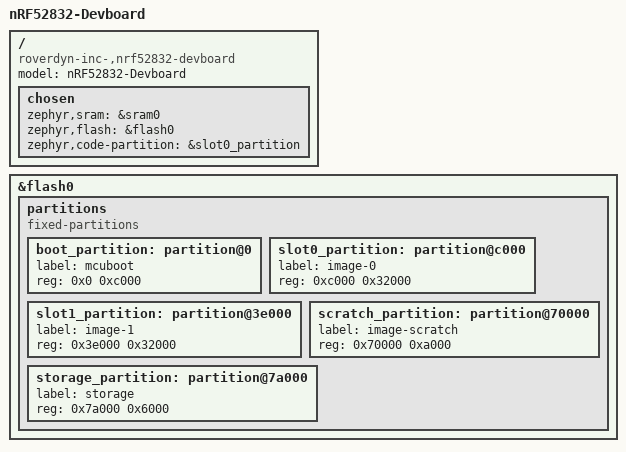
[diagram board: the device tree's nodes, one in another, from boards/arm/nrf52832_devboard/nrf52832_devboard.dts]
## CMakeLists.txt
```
cmake_minimum_required(VERSION 3.20.0)
find_package(Zephyr REQUIRED HINTS $ENV{ZEPHYR_BASE})

project(RTC-Interrupt-Examples)

target_sources(app PRIVATE src/main.c)
```

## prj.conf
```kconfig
# Config Debugger
CONFIG_CONSOLE=y
CONFIG_USE_SEGGER_RTT=y
CONFIG_RTT_CONSOLE=y
CONFIG_LOG=y
```

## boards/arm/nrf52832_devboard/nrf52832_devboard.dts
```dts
// Copyright (c) 2024 Nordic Semiconductor ASA
// SPDX-License-Identifier: Apache-2.0

/dts-v1/;
#include <nordic/nrf52832_qfaa.dtsi>

/ {
	model = "nRF52832-Devboard";
	compatible = "roverdyn-inc-,nrf52832-devboard";

	chosen {
		zephyr,sram = &sram0;
		zephyr,flash = &flash0;
		zephyr,code-partition = &slot0_partition;
	};
};

&flash0 {
	partitions {
		compatible = "fixed-partitions";
		#address-cells = <1>;
		#size-cells = <1>;

		boot_partition: partition@0 {
			label = "mcuboot";
			reg = <0x0 0xc000>;
		};
		slot0_partition: partition@c000 {
			label = "image-0";
			reg = <0xc000 0x32000>;
		};
		slot1_partition: partition@3e000 {
			label = "image-1";
			reg = <0x3e000 0x32000>;
		};
		scratch_partition: partition@70000 {
			label = "image-scratch";
			reg = <0x70000 0xa000>;
		};
		storage_partition: partition@7a000 {
			label = "storage";
			reg = <0x7a000 0x6000>;
		};
	};
};
```

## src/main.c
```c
#include <zephyr/kernel.h>

// RTC0 Interrupt Handler
void RTC2_IRQHandler();


// Global Variables
uint32_t counter = 0;
int main(void)
{
        // Initialize RTC
        NRF_RTC2->TASKS_CLEAR = 0x01;
        NRF_RTC2->INTENSET = RTC_INTENSET_COMPARE0_Enabled << RTC_INTENSET_COMPARE0_Pos;
        NRF_RTC2->EVTENSET = RTC_EVTENSET_COMPARE0_Enabled << RTC_EVTENSET_COMPARE0_Pos;
        NRF_RTC2->PRESCALER = 32;       // 32768/(32+1) = 992.96counts = 1sec
        NRF_RTC2->TASKS_START = 1;

        // Set RTC Compare Register
        counter = NRF_RTC2->COUNTER + 993;
        NRF_RTC2->CC[0] = counter;   // Call RTC1 Compare0 Handler after 1sec

        // Activate IRQ
        IRQ_DIRECT_CONNECT(RTC2_IRQn, 0, RTC2_IRQHandler, 0);
        irq_enable(RTC2_IRQn);
        
        while(true){
                // Main Loop
                //__WFI();
                k_usleep(1);
        }
        return 0;
}

void RTC2_IRQHandler(){
        // Function for RTC0 Interrupt/Events
        if(NRF_RTC2->EVENTS_COMPARE[0] == 1){
                NRF_RTC2->EVENTS_COMPARE[0] = 0;
                
                // Print message
                printk("Elapsed Time : %ds(%08d)\n", counter / 993, counter);        // 992.9 == 1sec

                // Set next compare register for repeat
                counter = NRF_RTC2->COUNTER + 993;
                NRF_RTC2->CC[0] = counter;
        }
}
```
